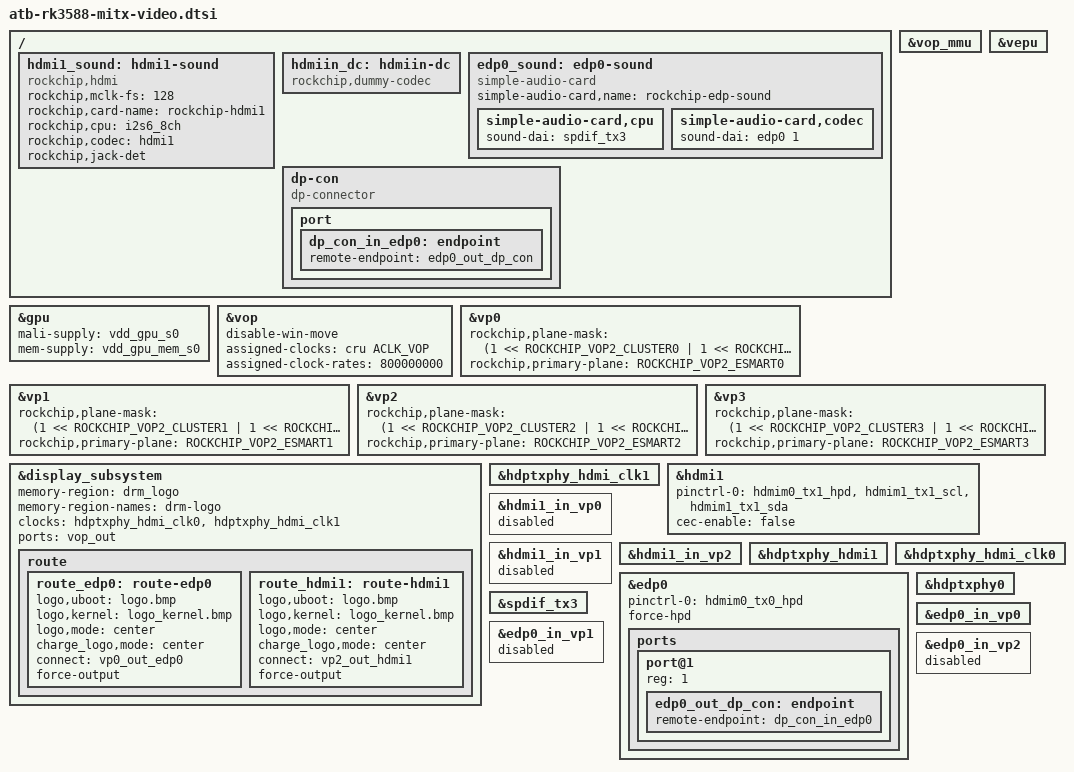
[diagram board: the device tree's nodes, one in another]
//=============================================================================
//  VIDEO   HDMI    DP
//=============================================================================

/ {
	hdmi1_sound: hdmi1-sound {
		status = "okay";
		compatible = "rockchip,hdmi";
		rockchip,mclk-fs = <128>;
		rockchip,card-name = "rockchip-hdmi1";
		rockchip,cpu = <&i2s6_8ch>;
		rockchip,codec = <&hdmi1>;
		rockchip,jack-det;
	};
	
	hdmiin_dc: hdmiin-dc {
		compatible = "rockchip,dummy-codec";
		#sound-dai-cells = <0>;
	};
	
	edp0_sound: edp0-sound {
		status = "okay";
		compatible = "simple-audio-card";
		simple-audio-card,name = "rockchip-edp-sound";

		simple-audio-card,cpu {
			sound-dai = <&spdif_tx3>;
		};
		simple-audio-card,codec {
			sound-dai = <&edp0 1>;
		};
	};
	
	dp-con {
		compatible = "dp-connector";
		status = "okay";

		port {
			dp_con_in_edp0: endpoint {
				remote-endpoint = <&edp0_out_dp_con>;
			};
		};
	};
};



&gpu {
	mali-supply = <&vdd_gpu_s0>;
	mem-supply = <&vdd_gpu_mem_s0>;
	status = "okay";
};

&vop {
	status = "okay";
	disable-win-move;
	assigned-clocks = <&cru ACLK_VOP>;
	assigned-clock-rates = <800000000>;
};

&vop_mmu {
	status = "okay";
};

&vepu {
	status = "okay";
};

// vp0 & vp1 splice for 8K output
&vp0 {
	rockchip,plane-mask = <(1 << ROCKCHIP_VOP2_CLUSTER0 | 1 << ROCKCHIP_VOP2_ESMART0)>;
	rockchip,primary-plane = <ROCKCHIP_VOP2_ESMART0>;
};

&vp1 {
	rockchip,plane-mask = <(1 << ROCKCHIP_VOP2_CLUSTER1 | 1 << ROCKCHIP_VOP2_ESMART1)>;
	rockchip,primary-plane = <ROCKCHIP_VOP2_ESMART1>;
};

&vp2 {
	rockchip,plane-mask = <(1 << ROCKCHIP_VOP2_CLUSTER2 | 1 << ROCKCHIP_VOP2_ESMART2)>;
	rockchip,primary-plane = <ROCKCHIP_VOP2_ESMART2>;
};

&vp3 {
	rockchip,plane-mask = <(1 << ROCKCHIP_VOP2_CLUSTER3 | 1 << ROCKCHIP_VOP2_ESMART3)>;
	rockchip,primary-plane = <ROCKCHIP_VOP2_ESMART3>;
};

&display_subsystem {
	memory-region = <&drm_logo>;
	memory-region-names = "drm-logo";
	
	clocks = <&hdptxphy_hdmi_clk0>,<&hdptxphy_hdmi_clk1>;
	clock-names = "hdmi0_phy_pll", "hdmi1_phy_pll";
	
	ports = <&vop_out>;

	route {
		route_edp0: route-edp0 {
			status = "okay";
			logo,uboot = "logo.bmp";
			logo,kernel = "logo_kernel.bmp";
			logo,mode = "center";
			charge_logo,mode = "center";
			connect = <&vp0_out_edp0>;
		};

		route_hdmi1: route-hdmi1 {
			status = "okay";
			logo,uboot = "logo.bmp";
			logo,kernel = "logo_kernel.bmp";
			logo,mode = "center";
			charge_logo,mode = "center";
			connect = <&vp2_out_hdmi1>;
			force-output;
		};
	};
};
//----------    HDMO1   ----------

&hdptxphy_hdmi_clk1 {
	status = "okay";
};

&hdmi1 {
	status = "okay";
	pinctrl-names = "default";
	pinctrl-0 = <&hdmim0_tx1_hpd &hdmim1_tx1_scl &hdmim1_tx1_sda>;
	cec-enable = "false";
};

&hdmi1_in_vp0 {
	status = "disabled";
};

&hdmi1_in_vp1 {
	status = "disabled";
};

&hdmi1_in_vp2 {
	status = "okay";
};

&route_hdmi1 {
	status = "okay";
	force-output;
	connect = <&vp2_out_hdmi1>;
};

&hdmi1_sound {
	status = "okay";
};

&hdptxphy_hdmi1 {
	status = "okay";
};
//----------    EDP0   ----------
&hdptxphy_hdmi_clk0 {
	status = "okay";
};

&edp0 {
	status = "okay";
	pinctrl-names = "default";
	pinctrl-0 = <&hdmim0_tx0_hpd>;
	#sound-dai-cells = <1>;
	force-hpd;

	ports {
		port@1 {
			reg = <1>;

			edp0_out_dp_con: endpoint {
				remote-endpoint = <&dp_con_in_edp0>;
			};
		};
	};

//	support-psr;
};

&hdptxphy0 {
	status = "okay";
};

&edp0_sound {
	status = "okay";
};

&spdif_tx3{
	status = "okay";
};

&edp0_in_vp0 {
	status = "okay";
};

&edp0_in_vp1 {
	status = "disabled";
};

&edp0_in_vp2 {
	status = "disabled";
};

&route_edp0 {
	status = "okay";
	force-output;
	connect = <&vp0_out_edp0>;
};
